VERSION "1.0"

NS_ :

BS_:

BU_: STM32 RASPI

BO_ 2566852609 VehicleStatus: 8 STM32
 SG_ speed : 0|16@1+ (0.01,0) [0|300] "km/h" RASPI
 SG_ StateOfCharge      : 16|8@1+ (1,0) [0|100] "%" RASPI

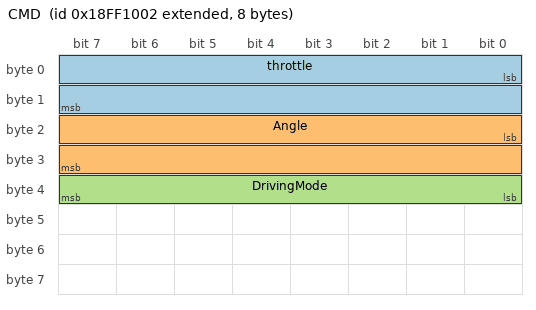
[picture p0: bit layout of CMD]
BO_ 2566852610 CMD: 8 RASPI
 SG_ throttle : 0|16@1+ (0.1,0) [0|100] "%" STM32
 SG_ Angle : 16|16@1- (0.1,0) [-450|450] "deg" STM32
 SG_ DrivingMode     : 32|8@1+ (1,0) [0|2] "" STM32

CM_ BO_ 2566852609 "status data vehicle VehicleSpeed,battery";
CM_ SG_ 2566852609 speed "Vehicle Speed";
CM_ BO_ 2566852610 "Commands to STM32";

VAL_ 2566852610 DrivingMode 0 "MANUAL" 1 "AI_ASSIST";
